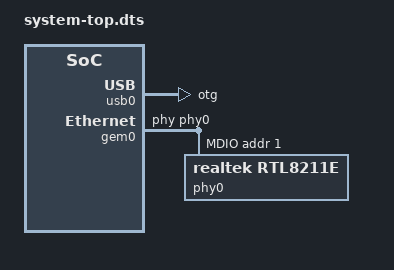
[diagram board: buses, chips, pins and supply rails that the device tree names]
/dts-v1/;
/include/ "system-conf.dtsi"
/ {
};
&clkc {
		ps-clk-frequency = <50000000>;
};
&flash0{
		compatible = "s25fl128s1";
};
&usb0{
		dr_mode = "otg";
};
&gem0{
		phy-handle = <&phy0>;
		mdio{
#address-cells = <1>;#size-cells = <0>;
phy0: phy@1{
			  compatible = "realtek,RTL8211E";
			  device_type = "ethernet-phy";
			  reg = <1>;
	  };
		};
};
&My_Time_Core_0 {
		compatible = "generic-uio";
};
